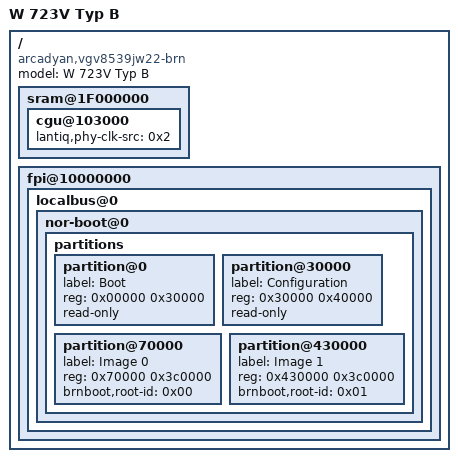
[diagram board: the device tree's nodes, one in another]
/dts-v1/;

#include "VGV8539JW22.dtsi"

/ {
	compatible = "arcadyan,vgv8539jw22-brn", "arcadyan,vgv8539jw22", "lantiq,xway", "lantiq,vr9";
	model = "W 723V Typ B";

	sram@1F000000 {
		cgu@103000 {
			lantiq,phy-clk-src = <0x2>;
		};
	};

	fpi@10000000 {
		localbus@0 {
			nor-boot@0 {
				partitions {
					partition@0 {
						label = "Boot";
						reg = <0x00000 0x30000>;
						read-only;
					};

					partition@30000 {
						label = "Configuration";
						reg = <0x30000 0x40000>;
						read-only;
					}

					partition@70000 {
						label = "Image 0";
						reg = <0x70000 0x3c0000>;
						brnboot,root-id = <0x00>;
					};

					partition@430000 {
						label = "Image 1";
						reg = <0x430000 0x3c0000>;
						brnboot,root-id = <0x01>;
					};
				};
			};
		};
	};
};
